# STM32GBK1CBT6 register map
File version: 1.6
CPU: CM4 r0p1, little endian, MPU, FPU, 4 interrupt priority bits
Registers are 32-bit, read-write, reset 0x0 unless marked. A register's access mark holds for its fields unless they carry their own. Offsets are from the block's base; [hi:lo] are bit positions; {n}, {i} and the like mark numbered series.

## LPUART1 — Universal synchronous asynchronous receiver transmitter
Base 0x40008000
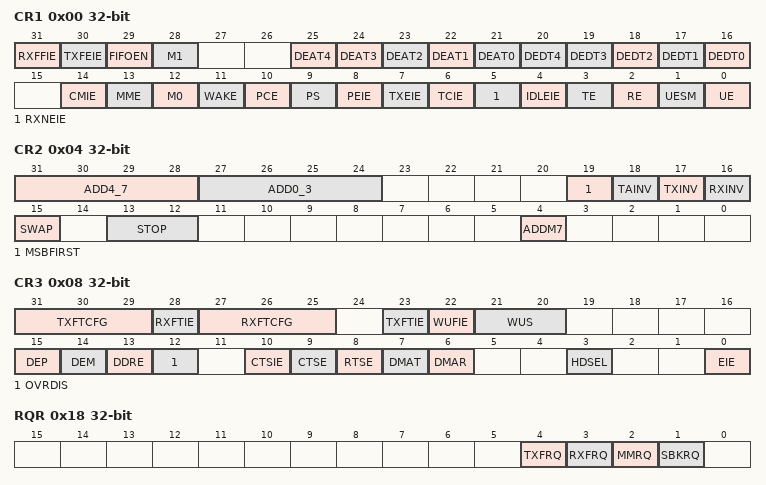
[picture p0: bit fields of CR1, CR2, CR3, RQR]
0x00 CR1 — Control register 1
  [31] RXFFIE
  [30] TXFEIE
  [29] FIFOEN
  [28] M1 — Word length
  [25] DEAT4 — Driver Enable assertion time
  [n+21] DEAT{n} (n=0..3)
  [20] DEDT4 — Driver Enable de-assertion time
  [n+16] DEDT{n} (n=0..3)
  [14] CMIE — Character match interrupt enable
  [13] MME — Mute mode enable
  [12] M0 — Word length
  [11] WAKE — Receiver wakeup method
  [10] PCE — Parity control enable
  [9] PS — Parity selection
  [8] PEIE — PE interrupt enable
  [7] TXEIE — interrupt enable
  [6] TCIE — Transmission complete interrupt enable
  [5] RXNEIE — RXNE interrupt enable
  [4] IDLEIE — IDLE interrupt enable
  [3] TE — Transmitter enable
  [2] RE — Receiver enable
  [1] UESM — USART enable in Stop mode
  [0] UE — USART enable
0x04 CR2 — Control register 2
  [31:28] ADD4_7 — Address of the USART node
  [27:24] ADD0_3 — Address of the USART node
  [19] MSBFIRST — Most significant bit first
  [18] TAINV — Binary data inversion
  [17] TXINV — TX pin active level inversion
  [16] RXINV — RX pin active level inversion
  [15] SWAP — Swap TX/RX pins
  [13:12] STOP — STOP bits
  [4] ADDM7 — 7-bit Address Detection/4-bit Address Detection
0x08 CR3 — Control register 3
  [31:29] TXFTCFG
  [28] RXFTIE
  [27:25] RXFTCFG
  [23] TXFTIE
  [22] WUFIE — Wakeup from Stop mode interrupt enable
  [21:20] WUS — Wakeup from Stop mode interrupt flag selection
  [15] DEP — Driver enable polarity selection
  [14] DEM — Driver enable mode
  [13] DDRE — DMA Disable on Reception Error
  [12] OVRDIS — Overrun Disable
  [10] CTSIE — CTS interrupt enable
  [9] CTSE — CTS enable
  [8] RTSE — RTS enable
  [7] DMAT — DMA enable transmitter
  [6] DMAR — DMA enable receiver
  [3] HDSEL — Half-duplex selection
  [0] EIE — Error interrupt enable
0x0C BRR — Baud rate register
  [19:0] BRR
0x18 RQR wo — Request register
  [4] TXFRQ
  [3] RXFRQ — Receive data flush request
  [2] MMRQ — Mute mode request
  [1] SBKRQ — Send break request
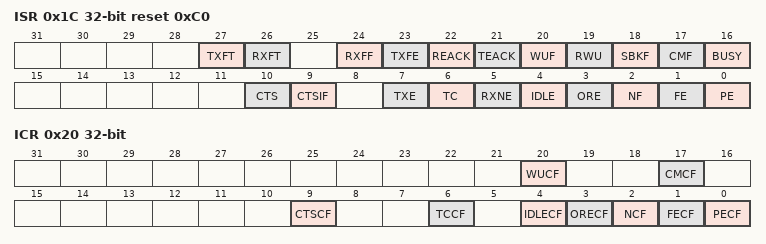
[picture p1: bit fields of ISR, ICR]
0x1C ISR ro reset 0xC0 — Interrupt & status register
  [27] TXFT, [26] RXFT, [24] RXFF, [23] TXFE, [22] REACK, [21] TEACK, [20] WUF, [19] RWU, [18] SBKF, [17] CMF, [16] BUSY, [10] CTS, [9] CTSIF, [7] TXE, [6] TC, [5] RXNE, [4] IDLE, [3] ORE, [2] NF, [1] FE, [0] PE
0x20 ICR wo — Interrupt flag clear register
  [20] WUCF — Wakeup from Stop mode clear flag
  [17] CMCF — Character match clear flag
  [9] CTSCF — CTS clear flag
  [6] TCCF — Transmission complete clear flag
  [4] IDLECF — Idle line detected clear flag
  [3] ORECF — Overrun error clear flag
  [2] NCF — Noise detected clear flag
  [1] FECF — Framing error clear flag
  [0] PECF — Parity error clear flag
0x24 RDR ro — Receive data register
  [8:0] RDR — Receive data value
0x28 TDR — Transmit data register
  [8:0] TDR — Transmit data value
0x2C PRESC — Prescaler register
  [3:0] PRESCALER

## SPI1 — Serial peripheral interface/Inter-IC sound
Base 0x40013000
Same registers: SPI2 0x40003800, SPI3 0x40003C00
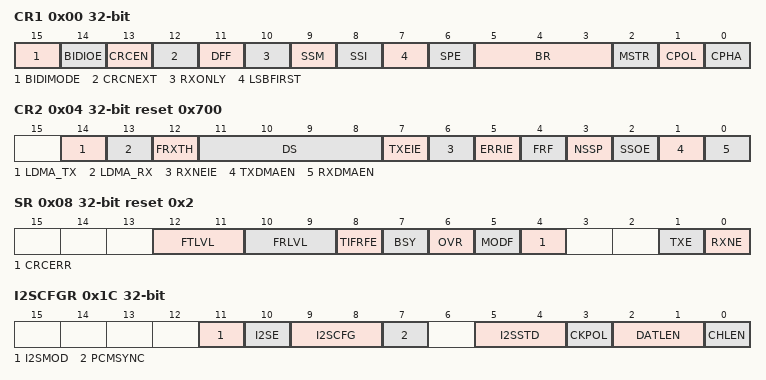
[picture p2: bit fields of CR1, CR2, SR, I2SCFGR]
0x00 CR1 — control register 1
  [15] BIDIMODE — Bidirectional data mode enable
  [14] BIDIOE — Output enable in bidirectional mode
  [13] CRCEN — Hardware CRC calculation enable
  [12] CRCNEXT — CRC transfer next
  [11] DFF — Data frame format
  [10] RXONLY — Receive only
  [9] SSM — Software slave management
  [8] SSI — Internal slave select
  [7] LSBFIRST — Frame format
  [6] SPE — SPI enable
  [5:3] BR — Baud rate control
  [2] MSTR — Master selection
  [1] CPOL — Clock polarity
  [0] CPHA — Clock phase
0x04 CR2 reset 0x700 — control register 2
  [14] LDMA_TX — Last DMA transfer for transmission
  [13] LDMA_RX — Last DMA transfer for reception
  [12] FRXTH — FIFO reception threshold
  [11:8] DS — Data size
  [7] TXEIE — Tx buffer empty interrupt enable
  [6] RXNEIE — RX buffer not empty interrupt enable
  [5] ERRIE — Error interrupt enable
  [4] FRF — Frame format
  [3] NSSP — NSS pulse management
  [2] SSOE — SS output enable
  [1] TXDMAEN — Tx buffer DMA enable
  [0] RXDMAEN — Rx buffer DMA enable
0x08 SR access per field reset 0x2 — status register
  [12:11] FTLVL ro — FIFO transmission level
  [10:9] FRLVL ro — FIFO reception level
  [8] TIFRFE ro — TI frame format error
  [7] BSY ro — Busy flag
  [6] OVR ro — Overrun flag
  [5] MODF ro — Mode fault
  [4] CRCERR rw — CRC error flag
  [1] TXE ro — Transmit buffer empty
  [0] RXNE ro — Receive buffer not empty
0x0C DR — data register
  [15:0] DR — Data register
0x10 CRCPR reset 0x7 — CRC polynomial register
  [15:0] CRCPOLY
0x14 RXCRCR ro — RX CRC register
  [15:0] RxCRC
0x18 TXCRCR ro — TX CRC register
  [15:0] TxCRC
0x1C I2SCFGR — configuration register
  [11] I2SMOD, [10] I2SE, [9:8] I2SCFG, [7] PCMSYNC, [5:4] I2SSTD, [3] CKPOL, [2:1] DATLEN, [0] CHLEN
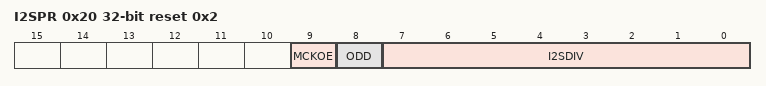
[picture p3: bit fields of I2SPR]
0x20 I2SPR reset 0x2 — prescaler register
  [9] MCKOE, [8] ODD, [7:0] I2SDIV
